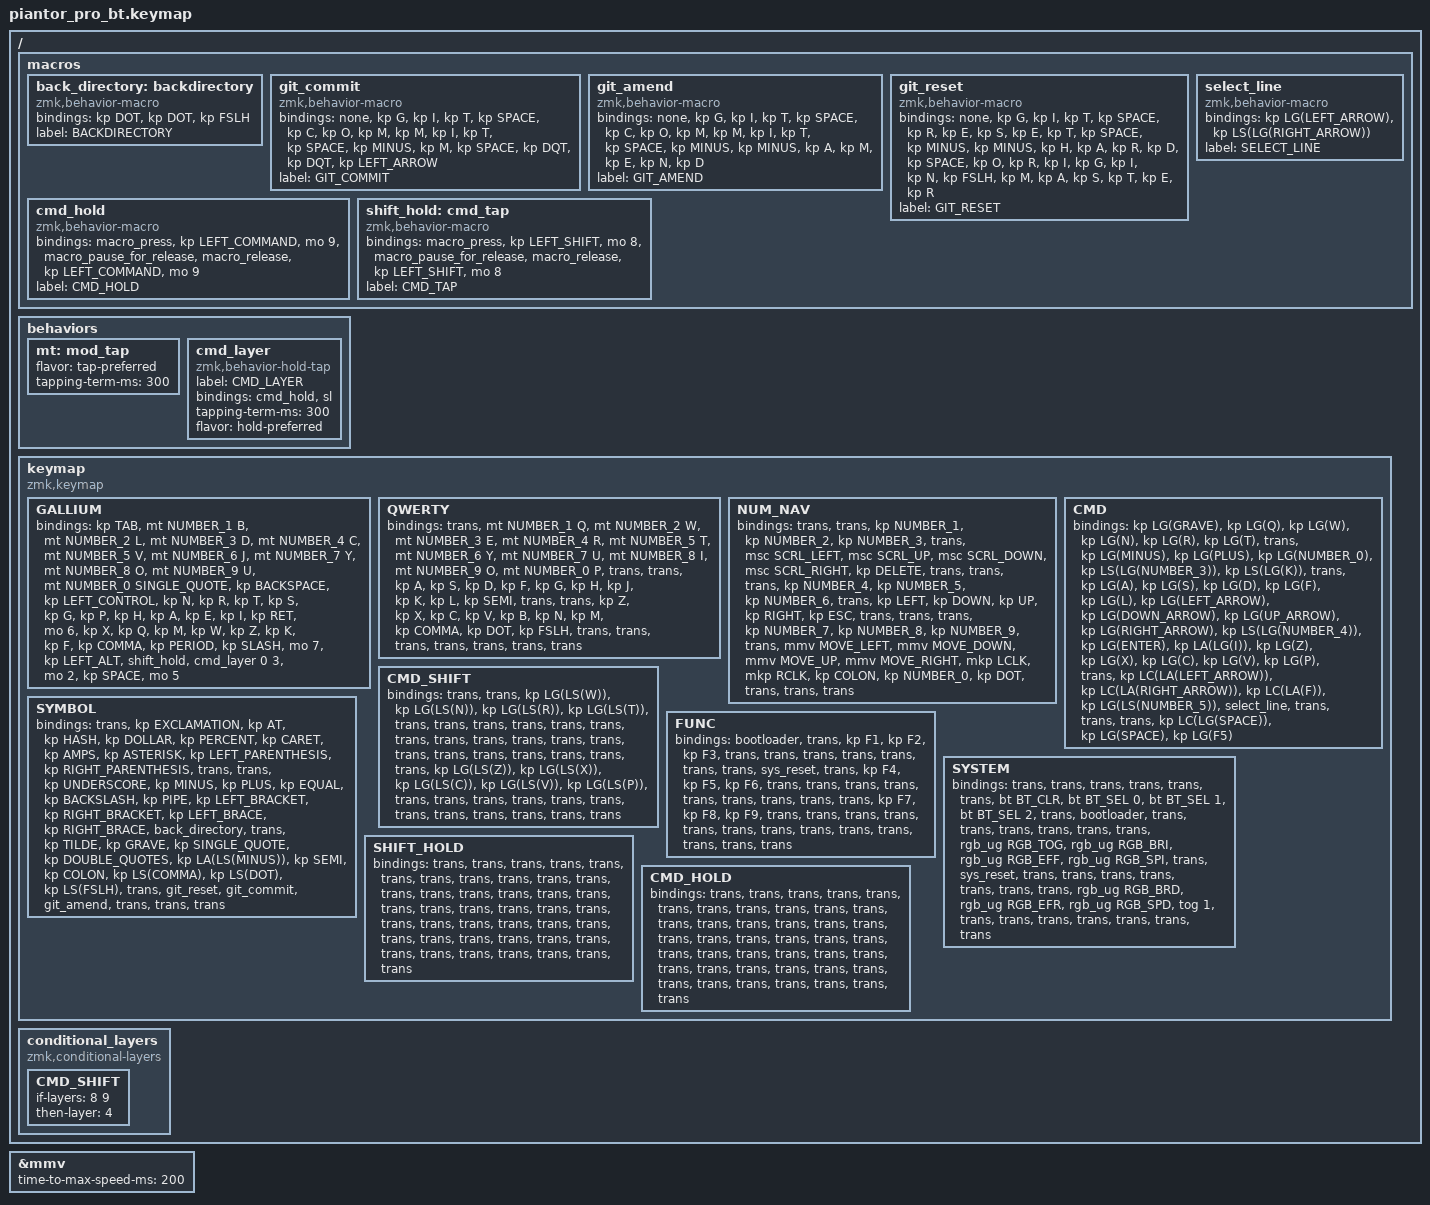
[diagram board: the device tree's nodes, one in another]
#define ZMK_POINTING_DEFAULT_MOVE_VAL 1800
#define ZMK_POINTING_DEFAULT_SCRL_VAL 20

#include <dt-bindings/zmk/behaviors.h>
#include <behaviors.dtsi>
#include <dt-bindings/zmk/bt.h>
#include <dt-bindings/zmk/keys.h>
#include <dt-bindings/zmk/pointing.h>
#include <dt-bindings/zmk/rgb.h>

&mt {
    tapping-term-ms = <300>;
    flavor = "tap-preferred";
};

&mmv { time-to-max-speed-ms = <200>; };

/ {
    macros {
        back_directory: backdirectory {
            compatible = "zmk,behavior-macro";
            #binding-cells = <0>;
            bindings = <&kp DOT &kp DOT &kp FSLH>;
            label = "BACKDIRECTORY";
        };

        git_commit: git_commit {
            compatible = "zmk,behavior-macro";
            #binding-cells = <0>;
            bindings = <&none &kp G &kp I &kp T &kp SPACE &kp C &kp O &kp M &kp M &kp I &kp T &kp SPACE &kp MINUS &kp M &kp SPACE &kp DQT &kp DQT &kp LEFT_ARROW>;
            label = "GIT_COMMIT";
        };

        git_amend: git_amend {
            compatible = "zmk,behavior-macro";
            #binding-cells = <0>;
            bindings = <&none &kp G &kp I &kp T &kp SPACE &kp C &kp O &kp M &kp M &kp I &kp T &kp SPACE &kp MINUS &kp MINUS &kp A &kp M &kp E &kp N &kp D>;
            label = "GIT_AMEND";
        };

        git_reset: git_reset {
            compatible = "zmk,behavior-macro";
            #binding-cells = <0>;
            bindings = <&none &kp G &kp I &kp T &kp SPACE &kp R &kp E &kp S &kp E &kp T &kp SPACE &kp MINUS &kp MINUS &kp H &kp A &kp R &kp D &kp SPACE &kp O &kp R &kp I &kp G &kp I &kp N &kp FSLH &kp M &kp A &kp S &kp T &kp E &kp R>;
            label = "GIT_RESET";
        };

        select_line: select_line {
            compatible = "zmk,behavior-macro";
            #binding-cells = <0>;
            bindings = <&kp LG(LEFT_ARROW) &kp LS(LG(RIGHT_ARROW))>;
            label = "SELECT_LINE";
        };

        cmd_hold: cmd_hold {
            compatible = "zmk,behavior-macro";
            #binding-cells = <0>;
            bindings =
                <&macro_press>,
                <&kp LEFT_COMMAND &mo 9>,
                <&macro_pause_for_release>,
                <&macro_release>,
                <&kp LEFT_COMMAND &mo 9>;

            label = "CMD_HOLD";
        };

        shift_hold: cmd_tap {
            compatible = "zmk,behavior-macro";
            #binding-cells = <0>;
            bindings =
                <&macro_press>,
                <&kp LEFT_SHIFT &mo 8>,
                <&macro_pause_for_release>,
                <&macro_release>,
                <&kp LEFT_SHIFT &mo 8>;

            label = "CMD_TAP";
        };
    };

    behaviors {
        mt: mod_tap {
            flavor = "tap-preferred";
            tapping-term-ms = <400>;
        };

        cmd_layer: cmd_layer {
            compatible = "zmk,behavior-hold-tap";
            label = "CMD_LAYER";
            bindings = <&cmd_hold>, <&sl>;

            #binding-cells = <2>;
            tapping-term-ms = <300>;
            flavor = "hold-preferred";
        };
    };

    keymap {
        compatible = "zmk,keymap";

        GALLIUM {
            bindings = <
&kp TAB  &mt NUMBER_1 B  &mt NUMBER_2 L  &mt NUMBER_3 D  &mt NUMBER_4 C  &mt NUMBER_5 V  &mt NUMBER_6 J  &mt NUMBER_7 Y  &mt NUMBER_8 O  &mt NUMBER_9 U  &mt NUMBER_0 SINGLE_QUOTE  &kp BACKSPACE  &kp LEFT_CONTROL  &kp N  &kp R  &kp T  &kp S  &kp G  &kp P  &kp H  &kp A  &kp E  &kp I  &kp RET  &mo 6  &kp X  &kp Q  &kp M  &kp W  &kp Z  &kp K  &kp F  &kp COMMA  &kp PERIOD  &kp SLASH  &mo 7  &kp LEFT_ALT  &shift_hold  &cmd_layer 0 3  &mo 2  &kp SPACE  &mo 5
            >;
        };

        QWERTY {
            bindings = <
&trans  &mt NUMBER_1 Q  &mt NUMBER_2 W  &mt NUMBER_3 E  &mt NUMBER_4 R  &mt NUMBER_5 T  &mt NUMBER_6 Y  &mt NUMBER_7 U  &mt NUMBER_8 I  &mt NUMBER_9 O  &mt NUMBER_0 P  &trans  &trans  &kp A  &kp S  &kp D  &kp F  &kp G  &kp H  &kp J  &kp K  &kp L  &kp SEMI  &trans  &trans  &kp Z  &kp X  &kp C  &kp V  &kp B  &kp N  &kp M  &kp COMMA  &kp DOT  &kp FSLH  &trans  &trans  &trans  &trans  &trans  &trans  &trans
            >;
        };

        NUM_NAV {
            bindings = <
&trans  &trans  &kp NUMBER_1  &kp NUMBER_2  &kp NUMBER_3  &trans  &msc SCRL_LEFT  &msc SCRL_UP  &msc SCRL_DOWN  &msc SCRL_RIGHT  &kp DELETE  &trans  &trans  &trans  &kp NUMBER_4  &kp NUMBER_5  &kp NUMBER_6  &trans  &kp LEFT  &kp DOWN  &kp UP  &kp RIGHT  &kp ESC  &trans  &trans  &trans  &kp NUMBER_7  &kp NUMBER_8  &kp NUMBER_9  &trans  &mmv MOVE_LEFT  &mmv MOVE_DOWN  &mmv MOVE_UP  &mmv MOVE_RIGHT  &mkp LCLK  &mkp RCLK  &kp COLON  &kp NUMBER_0  &kp DOT  &trans  &trans  &trans
            >;
        };

        CMD {
            bindings = <
&kp LG(GRAVE)  &kp LG(Q)  &kp LG(W)  &kp LG(N)  &kp LG(R)  &kp LG(T)  &trans  &kp LG(MINUS)  &kp LG(PLUS)  &kp LG(NUMBER_0)  &kp LS(LG(NUMBER_3))  &kp LS(LG(K))  &trans  &kp LG(A)  &kp LG(S)  &kp LG(D)  &kp LG(F)  &kp LG(L)  &kp LG(LEFT_ARROW)  &kp LG(DOWN_ARROW)  &kp LG(UP_ARROW)  &kp LG(RIGHT_ARROW)  &kp LS(LG(NUMBER_4))  &kp LG(ENTER)  &kp LA(LG(I))  &kp LG(Z)  &kp LG(X)  &kp LG(C)  &kp LG(V)  &kp LG(P)  &trans  &kp LC(LA(LEFT_ARROW))  &kp LC(LA(RIGHT_ARROW))  &kp LC(LA(F))  &kp LG(LS(NUMBER_5))  &select_line  &trans  &trans  &trans  &kp LC(LG(SPACE))  &kp LG(SPACE)  &kp LG(F5)
            >;
        };

        CMD_SHIFT {
            bindings = <
&trans  &trans  &kp LG(LS(W))  &kp LG(LS(N))  &kp LG(LS(R))  &kp LG(LS(T))  &trans  &trans  &trans  &trans  &trans  &trans  &trans  &trans  &trans  &trans  &trans  &trans  &trans  &trans  &trans  &trans  &trans  &trans  &trans  &kp LG(LS(Z))  &kp LG(LS(X))  &kp LG(LS(C))  &kp LG(LS(V))  &kp LG(LS(P))  &trans  &trans  &trans  &trans  &trans  &trans  &trans  &trans  &trans  &trans  &trans  &trans
            >;
        };

        SYMBOL {
            bindings = <
&trans  &kp EXCLAMATION  &kp AT  &kp HASH  &kp DOLLAR  &kp PERCENT  &kp CARET  &kp AMPS  &kp ASTERISK  &kp LEFT_PARENTHESIS  &kp RIGHT_PARENTHESIS  &trans  &trans  &kp UNDERSCORE  &kp MINUS  &kp PLUS  &kp EQUAL  &kp BACKSLASH  &kp PIPE  &kp LEFT_BRACKET  &kp RIGHT_BRACKET  &kp LEFT_BRACE  &kp RIGHT_BRACE  &back_directory  &trans  &kp TILDE  &kp GRAVE  &kp SINGLE_QUOTE  &kp DOUBLE_QUOTES  &kp LA(LS(MINUS))  &kp SEMI  &kp COLON  &kp LS(COMMA)  &kp LS(DOT)  &kp LS(FSLH)  &trans  &git_reset  &git_commit  &git_amend  &trans  &trans  &trans
            >;
        };

        FUNC {
            bindings = <
&bootloader  &trans  &kp F1  &kp F2  &kp F3  &trans  &trans  &trans  &trans  &trans  &trans  &trans  &sys_reset  &trans  &kp F4  &kp F5  &kp F6  &trans  &trans  &trans  &trans  &trans  &trans  &trans  &trans  &trans  &kp F7  &kp F8  &kp F9  &trans  &trans  &trans  &trans  &trans  &trans  &trans  &trans  &trans  &trans  &trans  &trans  &trans
            >;
        };

        SYSTEM {
            bindings = <
&trans  &trans  &trans  &trans  &trans  &trans  &bt BT_CLR  &bt BT_SEL 0  &bt BT_SEL 1  &bt BT_SEL 2  &trans  &bootloader  &trans  &trans  &trans  &trans  &trans  &trans  &rgb_ug RGB_TOG  &rgb_ug RGB_BRI  &rgb_ug RGB_EFF  &rgb_ug RGB_SPI  &trans  &sys_reset  &trans  &trans  &trans  &trans  &trans  &trans  &trans  &rgb_ug RGB_BRD  &rgb_ug RGB_EFR  &rgb_ug RGB_SPD  &tog 1  &trans  &trans  &trans  &trans  &trans  &trans  &trans
            >;
        };

        SHIFT_HOLD {
            bindings = <
&trans  &trans  &trans  &trans  &trans  &trans  &trans  &trans  &trans  &trans  &trans  &trans  &trans  &trans  &trans  &trans  &trans  &trans  &trans  &trans  &trans  &trans  &trans  &trans  &trans  &trans  &trans  &trans  &trans  &trans  &trans  &trans  &trans  &trans  &trans  &trans  &trans  &trans  &trans  &trans  &trans  &trans
            >;
        };

        CMD_HOLD {
            bindings = <
&trans  &trans  &trans  &trans  &trans  &trans  &trans  &trans  &trans  &trans  &trans  &trans  &trans  &trans  &trans  &trans  &trans  &trans  &trans  &trans  &trans  &trans  &trans  &trans  &trans  &trans  &trans  &trans  &trans  &trans  &trans  &trans  &trans  &trans  &trans  &trans  &trans  &trans  &trans  &trans  &trans  &trans
            >;
        };
    };

    conditional_layers {
        compatible = "zmk,conditional-layers";

        CMD_SHIFT {
            if-layers = <8 9>;
            then-layer = <4>;
        };
    };
};
